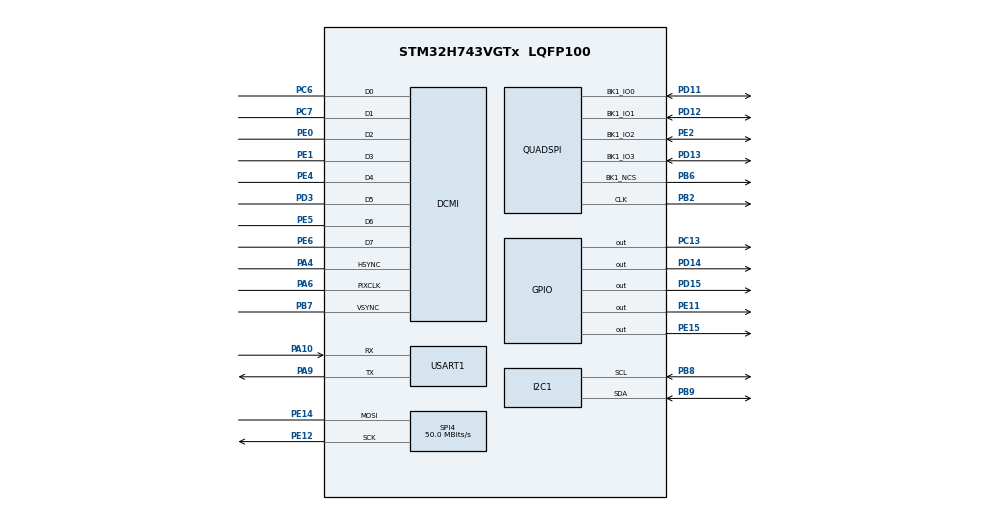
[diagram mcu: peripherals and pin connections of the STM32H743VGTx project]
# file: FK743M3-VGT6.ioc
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CORTEX_M7.AccessPermission_S-Cortex_Memory_Protection_Unit_Region1_Settings_S=MPU_REGION_FULL_ACCESS
CORTEX_M7.BaseAddress_S-Cortex_Memory_Protection_Unit_Region1_Settings_S=0x90000000
CORTEX_M7.CPU_DCache=Enabled
CORTEX_M7.CPU_ICache=Enabled
CORTEX_M7.Enable_S-Cortex_Memory_Protection_Unit_Region1_Settings_S=MPU_REGION_ENABLE
CORTEX_M7.MPU_Control=MPU_HFNMI_PRIVDEF
CORTEX_M7.Size_S-Cortex_Memory_Protection_Unit_Region1_Settings_S=MPU_REGION_SIZE_8MB
CORTEX_M7.TypeExtField_S-Cortex_Memory_Protection_Unit_Region1_Settings_S=MPU_TEX_LEVEL1
CORTEX_M7.default_mode_Activation=1
DCMI.JPEGMode=DCMI_JPEG_DISABLE
DCMI.PCKPolarity=DCMI_PCKPOLARITY_RISING
Dma.DCMI.1.Direction=DMA_PERIPH_TO_MEMORY
Dma.DCMI.1.EventEnable=DISABLE
Dma.DCMI.1.FIFOMode=DMA_FIFOMODE_DISABLE
Dma.DCMI.1.Instance=DMA2_Stream0
Dma.DCMI.1.MemDataAlignment=DMA_MDATAALIGN_WORD
Dma.DCMI.1.MemInc=DMA_MINC_ENABLE
Dma.DCMI.1.Mode=DMA_CIRCULAR
Dma.DCMI.1.PeriphDataAlignment=DMA_PDATAALIGN_WORD
Dma.DCMI.1.PeriphInc=DMA_PINC_DISABLE
Dma.DCMI.1.Polarity=HAL_DMAMUX_REQ_GEN_RISING
Dma.DCMI.1.Priority=DMA_PRIORITY_HIGH
Dma.DCMI.1.RequestNumber=1
Dma.DCMI.1.SignalID=NONE
Dma.DCMI.1.SyncEnable=DISABLE
Dma.DCMI.1.SyncPolarity=HAL_DMAMUX_SYNC_NO_EVENT
Dma.DCMI.1.SyncRequestNumber=1
Dma.DCMI.1.SyncSignalID=NONE
Dma.Request0=USART1_RX
Dma.Request1=DCMI
Dma.Request2=SPI4_TX
Dma.SPI4_TX.2.Direction=DMA_MEMORY_TO_PERIPH
Dma.SPI4_TX.2.EventEnable=DISABLE
Dma.SPI4_TX.2.FIFOMode=DMA_FIFOMODE_DISABLE
Dma.SPI4_TX.2.Instance=DMA1_Stream1
Dma.SPI4_TX.2.MemDataAlignment=DMA_MDATAALIGN_HALFWORD
Dma.SPI4_TX.2.MemInc=DMA_MINC_ENABLE
Dma.SPI4_TX.2.Mode=DMA_NORMAL
Dma.SPI4_TX.2.PeriphDataAlignment=DMA_PDATAALIGN_HALFWORD
Dma.SPI4_TX.2.PeriphInc=DMA_PINC_DISABLE
Dma.SPI4_TX.2.Polarity=HAL_DMAMUX_REQ_GEN_RISING
Dma.SPI4_TX.2.Priority=DMA_PRIORITY_HIGH
Dma.SPI4_TX.2.RequestNumber=1
Dma.SPI4_TX.2.SignalID=NONE
Dma.SPI4_TX.2.SyncEnable=DISABLE
Dma.SPI4_TX.2.SyncPolarity=HAL_DMAMUX_SYNC_NO_EVENT
Dma.SPI4_TX.2.SyncRequestNumber=1
Dma.SPI4_TX.2.SyncSignalID=NONE
Dma.USART1_RX.0.Direction=DMA_PERIPH_TO_MEMORY
Dma.USART1_RX.0.EventEnable=DISABLE
Dma.USART1_RX.0.FIFOMode=DMA_FIFOMODE_DISABLE
Dma.USART1_RX.0.Instance=DMA1_Stream0
Dma.USART1_RX.0.MemDataAlignment=DMA_MDATAALIGN_BYTE
Dma.USART1_RX.0.MemInc=DMA_MINC_ENABLE
Dma.USART1_RX.0.Mode=DMA_NORMAL
Dma.USART1_RX.0.PeriphDataAlignment=DMA_PDATAALIGN_BYTE
Dma.USART1_RX.0.PeriphInc=DMA_PINC_DISABLE
Dma.USART1_RX.0.Polarity=HAL_DMAMUX_REQ_GEN_RISING
Dma.USART1_RX.0.Priority=DMA_PRIORITY_LOW
Dma.USART1_RX.0.RequestNumber=1
Dma.USART1_RX.0.SignalID=NONE
Dma.USART1_RX.0.SyncEnable=DISABLE
Dma.USART1_RX.0.SyncPolarity=HAL_DMAMUX_SYNC_NO_EVENT
Dma.USART1_RX.0.SyncRequestNumber=1
Dma.USART1_RX.0.SyncSignalID=NONE
FREERTOS.Tasks01=defaultTask,24,128,StartDefaultTask,Default,NULL,Dynamic,NULL,NULL;Led_Disp_Task,8,128,Led_Disp,As weak,NULL,Dynamic,NULL,NULL;Uart_Proc_Task,16,512,Uart_Proc,As weak,NULL,Dynamic,NULL,NULL
I2C1.Timing=0x10C0ECFF
Mcu.Family=STM32H7
Mcu.Name=STM32H743VGTx
Mcu.Package=LQFP100
NVIC.DCMI_IRQn=true\:5\:0\:false\:false\:true\:true\:true\:true\:true
NVIC.DMA1_Stream0_IRQn=true\:5\:0\:false\:false\:true\:true\:false\:true\:true
NVIC.DMA1_Stream1_IRQn=true\:5\:0\:false\:false\:true\:true\:false\:true\:true
NVIC.DMA2_Stream0_IRQn=true\:5\:0\:true\:false\:true\:false\:false\:true\:true
NVIC.PriorityGroup=NVIC_PRIORITYGROUP_4
NVIC.SPI4_IRQn=true\:5\:0\:false\:false\:true\:true\:false\:true\:true
NVIC.TIM6_DAC_IRQn=true\:15\:0\:false\:false\:true\:false\:false\:true\:true
NVIC.TimeBase=TIM6_DAC_IRQn
NVIC.TimeBaseIP=TIM6
NVIC.USART1_IRQn=true\:5\:0\:false\:false\:true\:true\:true\:true\:true
PA10.Mode=Asynchronous
PA10.Signal=USART1_RX
PA13\ (JTMS/SWDIO).Mode=Serial_Wire
PA13\ (JTMS/SWDIO).Signal=DEBUG_JTMS-SWDIO
PA14\ (JTCK/SWCLK).Mode=Serial_Wire
PA14\ (JTCK/SWCLK).Signal=DEBUG_JTCK-SWCLK
PA4.GPIO_PuPd=GPIO_PULLUP
PA4.GPIO_Speed=GPIO_SPEED_FREQ_VERY_HIGH
PA4.Mode=Slave_8_bits_External_Synchro
PA4.Signal=DCMI_HSYNC
PA6.GPIO_PuPd=GPIO_PULLUP
PA6.GPIO_Speed=GPIO_SPEED_FREQ_VERY_HIGH
PA6.Mode=Slave_8_bits_External_Synchro
PA6.Signal=DCMI_PIXCLK
PA9.Mode=Asynchronous
PA9.Signal=USART1_TX
PB2.Mode=Single Bank 1
PB2.Signal=QUADSPI_CLK
PB6.Mode=Single Bank 1
PB6.Signal=QUADSPI_BK1_NCS
PB7.GPIO_PuPd=GPIO_PULLUP
PB7.GPIO_Speed=GPIO_SPEED_FREQ_VERY_HIGH
PB7.Mode=Slave_8_bits_External_Synchro
PB7.Signal=DCMI_VSYNC
PB8.Mode=I2C
PB8.Signal=I2C1_SCL
PB9.Mode=I2C
PB9.Signal=I2C1_SDA
PC13.Signal=GPIO_Output
PC14-OSC32_IN\ (OSC32_IN).Mode=LSE-External-Oscillator
PC14-OSC32_IN\ (OSC32_IN).Signal=RCC_OSC32_IN
PC15-OSC32_OUT\ (OSC32_OUT).Mode=LSE-External-Oscillator
PC15-OSC32_OUT\ (OSC32_OUT).Signal=RCC_OSC32_OUT
PC6.GPIO_Speed=GPIO_SPEED_FREQ_VERY_HIGH
PC6.Mode=Slave_8_bits_External_Synchro
PC6.Signal=DCMI_D0
PC7.GPIO_Speed=GPIO_SPEED_FREQ_VERY_HIGH
PC7.Mode=Slave_8_bits_External_Synchro
PC7.Signal=DCMI_D1
PD11.Mode=Single Bank 1
PD11.Signal=QUADSPI_BK1_IO0
PD12.Mode=Single Bank 1
PD12.Signal=QUADSPI_BK1_IO1
PD13.Mode=Single Bank 1
PD13.Signal=QUADSPI_BK1_IO3
PD14.Signal=GPIO_Output
PD15.GPIO_Speed=GPIO_SPEED_FREQ_LOW
PD15.Signal=GPIO_Output
PD3.GPIO_Speed=GPIO_SPEED_FREQ_VERY_HIGH
PD3.Mode=Slave_8_bits_External_Synchro
PD3.Signal=DCMI_D5
PE0.GPIO_Speed=GPIO_SPEED_FREQ_VERY_HIGH
PE0.Mode=Slave_8_bits_External_Synchro
PE0.Signal=DCMI_D2
PE1.GPIO_Speed=GPIO_SPEED_FREQ_VERY_HIGH
PE1.Mode=Slave_8_bits_External_Synchro
PE1.Signal=DCMI_D3
PE11.GPIO_Speed=GPIO_SPEED_FREQ_LOW
PE11.PinState=GPIO_PIN_SET
PE11.Signal=GPIO_Output
PE12.GPIO_Speed=GPIO_SPEED_FREQ_VERY_HIGH
PE12.Mode=Simplex_Bidirectional_Master
PE12.Signal=SPI4_SCK
PE14.GPIO_Speed=GPIO_SPEED_FREQ_VERY_HIGH
PE14.Mode=Simplex_Bidirectional_Master
PE14.Signal=SPI4_MOSI
PE15.GPIO_Speed=GPIO_SPEED_FREQ_LOW
PE15.Signal=GPIO_Output
PE2.Mode=Single Bank 1
PE2.Signal=QUADSPI_BK1_IO2
PE4.GPIO_Speed=GPIO_SPEED_FREQ_VERY_HIGH
PE4.Mode=Slave_8_bits_External_Synchro
PE4.Signal=DCMI_D4
PE5.GPIO_Speed=GPIO_SPEED_FREQ_VERY_HIGH
PE5.Mode=Slave_8_bits_External_Synchro
PE5.Signal=DCMI_D6
PE6.GPIO_Speed=GPIO_SPEED_FREQ_VERY_HIGH
PE6.Mode=Slave_8_bits_External_Synchro
PE6.Signal=DCMI_D7
PH0-OSC_IN\ (PH0).Mode=HSE-External-Oscillator
PH0-OSC_IN\ (PH0).Signal=RCC_OSC_IN
PH1-OSC_OUT\ (PH1).Mode=HSE-External-Oscillator
PH1-OSC_OUT\ (PH1).Signal=RCC_OSC_OUT
ProjectManager.HeapSize=0x200
ProjectManager.StackSize=0x400
ProjectManager.TargetToolchain=Makefile
QUADSPI.ClockPrescaler=1
QUADSPI.FifoThreshold=4
QUADSPI.FlashSize=22
QUADSPI.SampleShifting=QSPI_SAMPLE_SHIFTING_HALFCYCLE
RCC.ADCFreq_Value=50390625
RCC.APB1Freq_Value=100000000
RCC.APB2Freq_Value=100000000
RCC.APB3Freq_Value=100000000
RCC.APB4Freq_Value=100000000
RCC.CortexFreq_Value=400000000
RCC.D1PPRE=RCC_APB3_DIV2
RCC.D2PPRE1=RCC_APB1_DIV2
RCC.D2PPRE2=RCC_APB2_DIV2
RCC.D3PPRE=RCC_APB4_DIV2
RCC.DIVM1=2
RCC.DIVN1=64
RCC.DIVQ1=7
RCC.HCLKFreq_Value=200000000
RCC.HPRE=RCC_HCLK_DIV2
RCC.PLL2FRACN=0
RCC.PLL3FRACN=0
RCC.PLLFRACN=0
RCC.PLLSourceVirtual=RCC_PLLSOURCE_HSE
RCC.RTCClockSelection=RCC_RTCCLKSOURCE_LSE
RCC.SYSCLKFreq_VALUE=400000000
RCC.SYSCLKSource=RCC_SYSCLKSOURCE_PLLCLK
RCC.USBFreq_Value=114285714.28571428
SPI4.CalculateBaudRate=50.0 MBits/s
SPI4.DataSize=SPI_DATASIZE_8BIT
SPI4.Direction=SPI_DIRECTION_1LINE
SPI4.Mode=SPI_MODE_MASTER
SPI4.VirtualType=VM_MASTER
USART1.VirtualMode-Asynchronous=VM_ASYNC
VP_FREERTOS_VS_CMSIS_V2.Mode=CMSIS_V2
VP_MEMORYMAP_VS_MEMORYMAP.Mode=CurAppReg
VP_RTC_VS_RTC_Activate.Mode=RTC_Enabled
VP_RTC_VS_RTC_Calendar.Mode=RTC_Calendar
VP_SYS_VS_tim6.Mode=TIM6
board=custom

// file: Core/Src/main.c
/* USER CODE BEGIN Header */
/**
  ******************************************************************************
  * @file           : main.c
  * @brief          : Main program body
  ******************************************************************************
  * @attention
  *
  * Copyright (c) 2026 STMicroelectronics.
  * All rights reserved.
  *
  * This software is licensed under terms that can be found in the LICENSE file
  * in the root directory of this software component.
  * If no LICENSE file comes with this software, it is provided AS-IS.
  *
  ******************************************************************************
  */
/* USER CODE END Header */
#include "main.h"
#include "FreeRTOS.h"
#include "cmsis_os2.h"
#include "dcmi.h"
#include "dma.h"
#include "i2c.h"
#include "quadspi.h"
#include "rtc.h"
#include "spi.h"
#include "usart.h"
#include "gpio.h"

/* USER CODE BEGIN Includes */
#include "camera_task.h"
#include "vision_task.h"
/* USER CODE END Includes */

void SystemClock_Config(void);
static void MPU_Config(void);
void MX_FREERTOS_Init(void);

int main(void)
{

  /* MPU Configuration--------------------------------------------------------*/
  MPU_Config();

  /* Enable the CPU Cache */

  /* Enable I-Cache---------------------------------------------------------*/
  SCB_EnableICache();

  /* Enable D-Cache---------------------------------------------------------*/
  SCB_EnableDCache();

  /* MCU Configuration--------------------------------------------------------*/

  /* Reset of all peripherals, Initializes the Flash interface and the Systick. */
  HAL_Init();

  /* Configure the system clock */
  SystemClock_Config();

  /* Initialize all configured peripherals */
  MX_GPIO_Init();
  MX_DMA_Init();
  MX_RTC_Init();
  MX_USART1_UART_Init();
  MX_QUADSPI_Init();
  MX_DCMI_Init();
  MX_I2C1_Init();
  MX_SPI4_Init();
  /* USER CODE BEGIN 2 */
  Camera_Init();
  Vision_Init();
  /* USER CODE END 2 */

  /* Init scheduler */
  osKernelInitialize();  /* Call init function for freertos objects (in cmsis_os2.c) */
  MX_FREERTOS_Init();

  /* Start scheduler */
  osKernelStart();

  /* We should never get here as control is now taken by the scheduler */

  /* Infinite loop */
  while (1)
  {

  }
}

void SystemClock_Config(void)
{
  RCC_OscInitTypeDef RCC_OscInitStruct = {0};
  RCC_ClkInitTypeDef RCC_ClkInitStruct = {0};

  /** Supply configuration update enable
  */
  HAL_PWREx_ConfigSupply(PWR_LDO_SUPPLY);

  /** Configure the main internal regulator output voltage
  */
  __HAL_PWR_VOLTAGESCALING_CONFIG(PWR_REGULATOR_VOLTAGE_SCALE1);

  while(!__HAL_PWR_GET_FLAG(PWR_FLAG_VOSRDY)) {}

  /** Configure LSE Drive Capability
  */
  HAL_PWR_EnableBkUpAccess();
  __HAL_RCC_LSEDRIVE_CONFIG(RCC_LSEDRIVE_LOW);

  /** Initializes the RCC Oscillators according to the specified parameters
  * in the RCC_OscInitTypeDef structure.
  */
  RCC_OscInitStruct.OscillatorType = RCC_OSCILLATORTYPE_HSE|RCC_OSCILLATORTYPE_LSE;
  RCC_OscInitStruct.HSEState = RCC_HSE_ON;
  RCC_OscInitStruct.LSEState = RCC_LSE_ON;
  RCC_OscInitStruct.PLL.PLLState = RCC_PLL_ON;
  RCC_OscInitStruct.PLL.PLLSource = RCC_PLLSOURCE_HSE;
  RCC_OscInitStruct.PLL.PLLM = 2;
  RCC_OscInitStruct.PLL.PLLN = 64;
  RCC_OscInitStruct.PLL.PLLP = 2;
  RCC_OscInitStruct.PLL.PLLQ = 7;
  RCC_OscInitStruct.PLL.PLLR = 2;
  RCC_OscInitStruct.PLL.PLLRGE = RCC_PLL1VCIRANGE_3;
  RCC_OscInitStruct.PLL.PLLVCOSEL = RCC_PLL1VCOWIDE;
  RCC_OscInitStruct.PLL.PLLFRACN = 0;
  if (HAL_RCC_OscConfig(&RCC_OscInitStruct) != HAL_OK)
  {
    Error_Handler();
  }

  /** Initializes the CPU, AHB and APB buses clocks
  */
  RCC_ClkInitStruct.ClockType = RCC_CLOCKTYPE_HCLK|RCC_CLOCKTYPE_SYSCLK
                              |RCC_CLOCKTYPE_PCLK1|RCC_CLOCKTYPE_PCLK2
                              |RCC_CLOCKTYPE_D3PCLK1|RCC_CLOCKTYPE_D1PCLK1;
  RCC_ClkInitStruct.SYSCLKSource = RCC_SYSCLKSOURCE_PLLCLK;
  RCC_ClkInitStruct.SYSCLKDivider = RCC_SYSCLK_DIV1;
  RCC_ClkInitStruct.AHBCLKDivider = RCC_HCLK_DIV2;
  RCC_ClkInitStruct.APB3CLKDivider = RCC_APB3_DIV2;
  RCC_ClkInitStruct.APB1CLKDivider = RCC_APB1_DIV2;
  RCC_ClkInitStruct.APB2CLKDivider = RCC_APB2_DIV2;
  RCC_ClkInitStruct.APB4CLKDivider = RCC_APB4_DIV2;

  if (HAL_RCC_ClockConfig(&RCC_ClkInitStruct, FLASH_LATENCY_2) != HAL_OK)
  {
    Error_Handler();
  }
}

 /* MPU Configuration */

void MPU_Config(void)
{
  MPU_Region_InitTypeDef MPU_InitStruct = {0};

  /* Disables the MPU */
  HAL_MPU_Disable();

  /** Initializes and configures the Region and the memory to be protected
  */
  MPU_InitStruct.Enable = MPU_REGION_ENABLE;
  MPU_InitStruct.Number = MPU_REGION_NUMBER0;
  MPU_InitStruct.BaseAddress = 0x0;
  MPU_InitStruct.Size = MPU_REGION_SIZE_4GB;
  MPU_InitStruct.SubRegionDisable = 0x87;
  MPU_InitStruct.TypeExtField = MPU_TEX_LEVEL0;
  MPU_InitStruct.AccessPermission = MPU_REGION_NO_ACCESS;
  MPU_InitStruct.DisableExec = MPU_INSTRUCTION_ACCESS_DISABLE;
  MPU_InitStruct.IsShareable = MPU_ACCESS_SHAREABLE;
  MPU_InitStruct.IsCacheable = MPU_ACCESS_NOT_CACHEABLE;
  MPU_InitStruct.IsBufferable = MPU_ACCESS_NOT_BUFFERABLE;

  HAL_MPU_ConfigRegion(&MPU_InitStruct);

  /** Initializes and configures the Region and the memory to be protected
  */
  MPU_InitStruct.Number = MPU_REGION_NUMBER1;
  MPU_InitStruct.BaseAddress = 0x90000000;
  MPU_InitStruct.Size = MPU_REGION_SIZE_8MB;
  MPU_InitStruct.SubRegionDisable = 0x0;
  MPU_InitStruct.TypeExtField = MPU_TEX_LEVEL1;
  MPU_InitStruct.AccessPermission = MPU_REGION_FULL_ACCESS;
  MPU_InitStruct.DisableExec = MPU_INSTRUCTION_ACCESS_ENABLE;
  MPU_InitStruct.IsShareable = MPU_ACCESS_NOT_SHAREABLE;

  HAL_MPU_ConfigRegion(&MPU_InitStruct);
  /* Enables the MPU */
  HAL_MPU_Enable(MPU_HFNMI_PRIVDEF);

}

void HAL_TIM_PeriodElapsedCallback(TIM_HandleTypeDef *htim)
{
  if (htim->Instance == TIM6)
  {
    HAL_IncTick();
  }
}

void Error_Handler(void)
{
  __disable_irq();
  while (1)
  {
  }
}

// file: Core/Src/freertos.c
/* USER CODE BEGIN Header */
/**
  ******************************************************************************
  * File Name          : freertos.c
  * Description        : Code for freertos applications
  ******************************************************************************
  * @attention
  *
  * Copyright (c) 2026 STMicroelectronics.
  * All rights reserved.
  *
  * This software is licensed under terms that can be found in the LICENSE file
  * in the root directory of this software component.
  * If no LICENSE file comes with this software, it is provided AS-IS.
  *
  ******************************************************************************
  */
/* USER CODE END Header */

#include "FreeRTOS.h"
#include "task.h"
#include "main.h"
#include "FreeRTOS.h"
#include "cmsis_os2.h"

/* Definitions for defaultTask */
osThreadId_t defaultTaskHandle;
const osThreadAttr_t defaultTask_attributes = {
  .name = "defaultTask",
  .stack_size = 128 * 4,
  .priority = (osPriority_t) osPriorityNormal,
};
/* Definitions for Led_Disp_Task */
osThreadId_t Led_Disp_TaskHandle;
const osThreadAttr_t Led_Disp_Task_attributes = {
  .name = "Led_Disp_Task",
  .stack_size = 128 * 4,
  .priority = (osPriority_t) osPriorityLow,
};
/* Definitions for Uart_Proc_Task */
osThreadId_t Uart_Proc_TaskHandle;
const osThreadAttr_t Uart_Proc_Task_attributes = {
  .name = "Uart_Proc_Task",
  .stack_size = 512 * 4,
  .priority = (osPriority_t) osPriorityBelowNormal,
};

void StartDefaultTask(void *argument);
void Led_Disp(void *argument);
void Uart_Proc(void *argument);

void MX_FREERTOS_Init(void); /* (MISRA C 2004 rule 8.1) */

void MX_FREERTOS_Init(void) {

  /* Create the thread(s) */
  /* creation of defaultTask */
  defaultTaskHandle = osThreadNew(StartDefaultTask, NULL, &defaultTask_attributes);

  /* creation of Led_Disp_Task */
  Led_Disp_TaskHandle = osThreadNew(Led_Disp, NULL, &Led_Disp_Task_attributes);

  /* creation of Uart_Proc_Task */
  Uart_Proc_TaskHandle = osThreadNew(Uart_Proc, NULL, &Uart_Proc_Task_attributes);

}

void StartDefaultTask(void *argument)
{
  for(;;)
  {
    osDelay(1);
  }
}

__weak void Led_Disp(void *argument)
{
  for(;;)
  {
    osDelay(1);
  }
}

__weak void Uart_Proc(void *argument)
{
  for(;;)
  {
    osDelay(1);
  }
}
